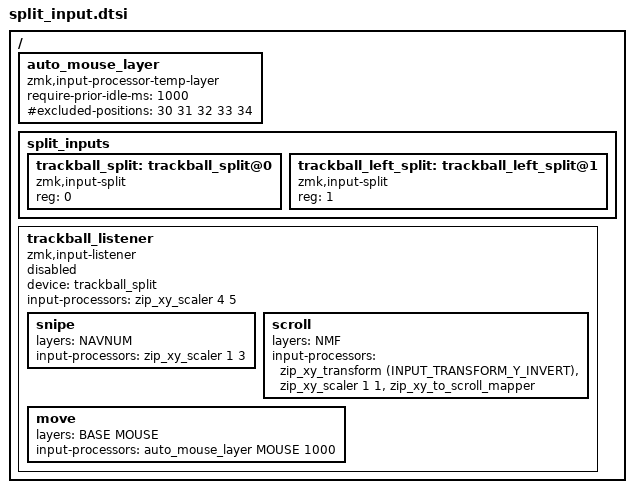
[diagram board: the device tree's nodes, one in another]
#include "behaviors.dtsi"
#include <dt-bindings/zmk/input_transform.h>
#include <input/processors.dtsi>

#include "../../../config/layers.h"

/ {
  auto_mouse_layer: auto_mouse_layer {
    compatible = "zmk,input-processor-temp-layer";
    #input-processor-cells = <2>;
    require-prior-idle-ms = <1000>;
    #excluded-positions = <30 31 32 33 34>;
  };

  split_inputs {
    #address-cells = <1>;
    #size-cells = <0>;

    trackball_split: trackball_split@0 {
      compatible = "zmk,input-split";
      reg = <0>;
    };

    trackball_left_split: trackball_left_split@1 {
      compatible = "zmk,input-split";
      reg = <1>;
    };
  };

  trackball_listener: trackball_listener {
    compatible = "zmk,input-listener";
    status = "disabled";
    device = <&trackball_split>;

    input-processors = <&zip_xy_scaler 4 5>;

    snipe {
      layers = <NAVNUM>;
      input-processors = <&zip_xy_scaler 1 3>;
    };

    scroll {
      layers = <NMF>;
      input-processors = <&zip_xy_transform (INPUT_TRANSFORM_Y_INVERT)>, <&zip_xy_scaler 1 1>, <&zip_xy_to_scroll_mapper>;
    };

    move {
      layers = <BASE MOUSE>;
      input-processors = <&auto_mouse_layer MOUSE 1000>;
    };
  };

  // trackball_left_listener: trackball_left_listener {
  //   compatible = "zmk,input-listener";
  //   status = "disabled";
  //   device = <&trackball_left_split>;

  //   // input-processors = <&zip_xy_scaler 4 5>;

  //   snipe {
  //     layers = <NAVNUM>;
  //     input-processors = <&zip_xy_scaler 1 3>;
  //   };

  //   scroll {
  //     layers = <NMF>;
  //     input-processors = <&zip_xy_transform (INPUT_TRANSFORM_Y_INVERT)>, <&zip_xy_scaler 1 1>, <&zip_xy_to_scroll_mapper>;
  //   };
  // };
};


